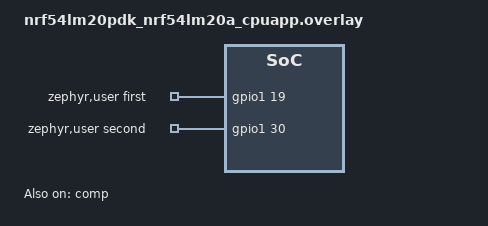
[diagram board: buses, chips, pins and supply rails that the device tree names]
/* Two loopbacks are used
 * Each loopback is between analog input and GPIO.
 * first-gpios (P1.19) -> AIN3 (P1.29)
 * second-gpios (P1.30, AIN2) -> AIN1 (P1.31)
 * AIN5 (P1.05) tied to low (UART1_RX)
 */

/ {
	aliases {
		test-comp = &comp;
	};

	zephyr,user {
		first-gpios = <&gpio1 19 GPIO_ACTIVE_HIGH>;
		second-gpios = <&gpio1 30 GPIO_ACTIVE_HIGH>;
	};
};

&gpio1 {
	status = "okay";
};

&comp {
	status = "okay";
	psel = "AIN4";
	refsel = "AREF";
	extrefsel= "AIN3";
	sp-mode = "NORMAL";
	th-up = <36>;
	th-down = <30>;
	isource = "DISABLED";
	enable-hyst;
};
